# CC23x0 register map
File version: 1.0
CPU: CM0+ r0p4, little endian, no MPU, no FPU, VTOR, 3 interrupt priority bits
Registers are 32-bit, read-write, reset 0x0 unless marked. A register's access mark holds for its fields unless they carry their own. Offsets are from the block's base; [hi:lo] are bit positions; {n}, {i} and the like mark numbered series; 'fields as' and 'values as' point back to an identical list.

## BPU
Base 0xE0002000
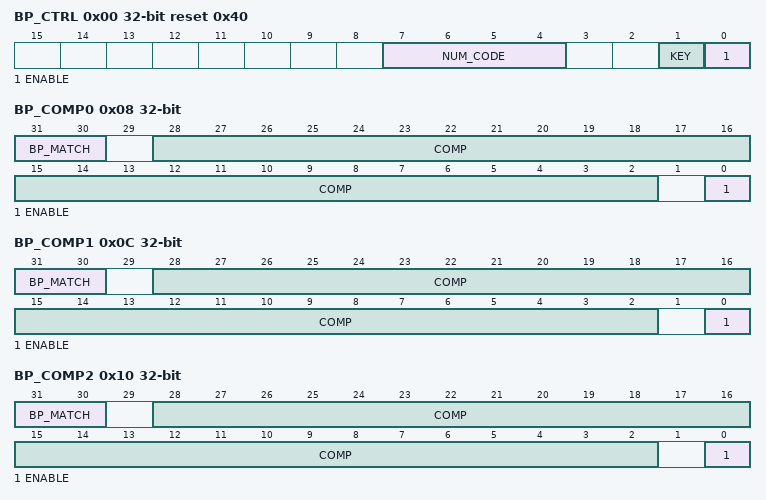
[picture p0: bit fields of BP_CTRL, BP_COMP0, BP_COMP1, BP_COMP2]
0x00 BP_CTRL reset 0x40 — Breakpoint Control Register Use the Breakpoint Control Register to enable the Breakpoint block
  [7:4] NUM_CODE ro — Number of comparators.
  [1] KEY wo — Key field. To write to the Breakpoint Control Register, you must write a 1 to this write-only bit. This bit reads as zero.
  [0] ENABLE — Breakpoint unit enable bit. DBGRESETn clears the ENABLE bit.
    1=BKPT_EN (Breakpoint unit enabled); 0=BKPT_DIS (Breakpoint unit disabled)
0x08 BP_COMP0 — Breakpoint Comparator Register 0 Use the Breakpoint Comparator Registers to store the values to compare with the instruction address.
  [31:30] BP_MATCH — This selects what happens when the COMP address is matched
    3=BKPT_COMP_BOTH (set breakpoint on both lower and upper halfwords); 2=BKPT_COMP_HI (set breakpoint on upper halfword, lower is unaffected); 1=BKPT_COMP_LOW (set breakpoint on lower halfword, upper is unaffected); 0=BKPT_COMP_NONE (no breakpoint generated)
  [28:2] COMP — Comparison address, UNKNOWN on reset.
  [0] ENABLE — Compare enable for Breakpoint Comparator Register 0. The ENABLE bit of BP_CTRL must also be set to enable comparisons. DBGRESETn clears the ENABLE bit.
    1=BKPT_COMP_DIS (Breakpoint Comparator Register 0 compare enabled); 0=BKPT_COMP_EN (Breakpoint Comparator Register 0 compare disabled)
0x0C BP_COMP1 — Breakpoint Comparator Register 1 Use the Breakpoint Comparator Registers to store the values to compare with the instruction address.
  [31:30] BP_MATCH — This selects what happens when the COMP address is matched
    3=BKPT_COMP_BOTH (Set breakpoint on both lower and upper halfwords); 2=BKPT_COMP_HI (Set breakpoint on upper halfword, lower is unaffected); 1=BKPT_COMP_LOW (Set breakpoint on lower halfword, upper is unaffected); 0=BKPT_COMP_NONE (No breakpoint generated)
  [28:2] COMP — Comparison address. Although it is architecturally Unpredictable whether breakpoint matches on the address of the second halfword of a 32-bit instruction to generates a debug event, in this processor it is predictable and a debug event is generated.
  [0] ENABLE — Comparison address, UNKNOWN on reset.
    1=BKPT_COMP_DIS (Breakpoint Comparator Register 1 compare enabled); 0=BKPT_COMP_EN (Breakpoint Comparator Register 1 compare disabled)
0x10 BP_COMP2 — Breakpoint Comparator Register 2 Use the Breakpoint Comparator Registers to store the values to compare with the PC address.
  [31:30] BP_MATCH — This selects what happens when the COMP address is matched
    3=BKPT_COMP_BOTH (Set breakpoint on both lower and upper halfwords); 2=BKPT_COMP_HI (Set breakpoint on upper halfword, lower is unaffected); 1=BKPT_COMP_LOW (Set breakpoint on lower halfword, upper is unaffected); 0=BKPT_COMP_NONE (No breakpoint matching)
  [28:2] COMP — Comparison address, UNKNOWN on reset.
  [0] ENABLE — Compare enable for Breakpoint Comparator Register 2. The ENABLE bit of BP_CTRL must also be set to enable comparisons. DBGRESETn clears the ENABLE bit.
    1=BKPT_COMP_DIS (Breakpoint Comparator Register 2 compare enabled); 0=BKPT_COMP_EN (Breakpoint Comparator Register 2 compare disabled)
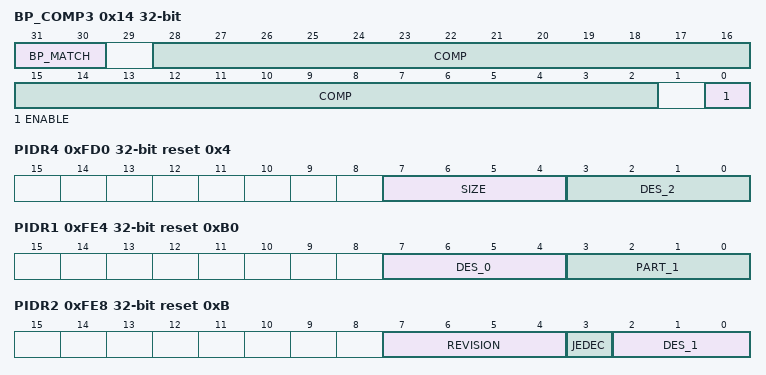
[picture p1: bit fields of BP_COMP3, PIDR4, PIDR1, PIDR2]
0x14 BP_COMP3 — Breakpoint Comparator Register 3 Use the Breakpoint Comparator Registers to store the values to compare with the instruction address.
  [31:30] BP_MATCH — This selects what happens when the COMP address is matched
    values as BP_COMP1.BP_MATCH
  [28:2] COMP — Comparison address, UNKNOWN on reset.
  [0] ENABLE — Compare enable for Breakpoint Comparator Register 3. The ENABLE bit of BP_CTRL must also be set to enable comparisons. DBGRESETn clears the ENABLE bit.
    1=BKPT_COMP_DIS (Breakpoint Comparator Register 3 compare enabled); 0=BKPT_COMP_EN (Breakpoint Comparator Register 3 compare disabled)
0xFD0 PIDR4 reset 0x4 — Peripheral ID Register 4 Part of the set of Peripheral Identification registers. Contains part of the designer identity and the memory footprint indicator.
  [7:4] SIZE ro — This is a 4-bit value that indicates the total contiguous size of the memory window used by this component in powers of 2 from the standard 4KB. If a component only requires the standard 4KB then this should read as 0x0, 4KB only, for 8KB set to 0x1, 16KB == 0x2, 32KB == 0x3, and so on.
  [3:0] DES_2 ro — Number of JEDEC continuation codes. Indicates the designer of the component (along with the identity code)
{0xFC0+4i} PIDR{i} (i=5..7) — Peripheral ID Register {i} Reserved
0xFE0 PIDR0 reset 0xB — Peripheral ID Register 0 Part of the set of Peripheral Identification registers. Contains part of the designer specific part number.
  [7:0] PART_0 ro — Bits [7:0] of the component's part number. This is selected by the designer of the component.
0xFE4 PIDR1 reset 0xB0 — Peripheral ID Register 1 Part of the set of Peripheral Identification registers. Contains part of the designer specific part number and part of the designer identity.
  [7:4] DES_0 ro — Bits [3:0] of the JEDEC identity code indicating the designer of the component (along with the continuation code)
  [3:0] PART_1 ro — Bits [11:8] of the component's part number. This is selected by the designer of the component.
0xFE8 PIDR2 reset 0xB — Peripheral ID Register 2 Part of the set of Peripheral Identification registers. Contains part of the designer identity and the product revision.
  [7:4] REVISION ro — The Revision field is an incremental value starting at 0x0 for the first design of this component. This only increases by 1 for both major and minor revisions and is simply used as a look-up to establish the exact major/minor revision.
  [3] JEDEC ro — Always set. Indicates that a JEDEC assigned value is used
  [2:0] DES_1 ro — Bits [6:4] of the JEDEC identity code indicating the designer of the component (along with the continuation code)
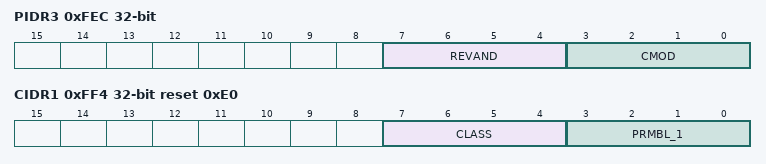
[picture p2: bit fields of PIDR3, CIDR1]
0xFEC PIDR3 — Peripheral ID Register 3 Part of the set of Peripheral Identification registers. Contains the RevAnd and Customer Modified fields.
  [7:4] REVAND ro — This field indicates minor errata fixes specific to this design, for example metal fixes after implementation. In most cases this field is zero. It is recommended that component designers ensure this field can be changed by a metal fix if required, for example by driving it from registers that reset to zero.
  [3:0] CMOD ro — Where the component is reusable IP, this value indicates if the customer has modified the behavior of the component. In most cases this field is zero.
0xFF0 CIDR0 reset 0xD — Component ID Register 0 A component identification register, that indicates that the identification registers are present.
  [7:0] PRMBL_0 ro — Contains bits [7:0] of the component identification
0xFF4 CIDR1 reset 0xE0 — Component ID Register 1 A component identification register, that indicates that the identification registers are present. This register also indicates the component class.
  [7:4] CLASS ro — Class of the component. E.g. ROM table, CoreSight component etc. Constitutes bits [15:12] of the component identification.
  [3:0] PRMBL_1 ro — Contains bits [11:8] of the component identification
0xFF8 CIDR2 reset 0x5 — Component ID Register 2 A component identification register, that indicates that the identification registers are present.
  [7:0] PRMBL_2 ro — Contains bits [23:16] of the component identification
0xFFC CIDR3 reset 0xB1 — Component ID Register 3 A component identification register, that indicates that the identification registers are present.
  [7:0] PRMBL_3 ro — Contains bits [31:24] of the component identification
